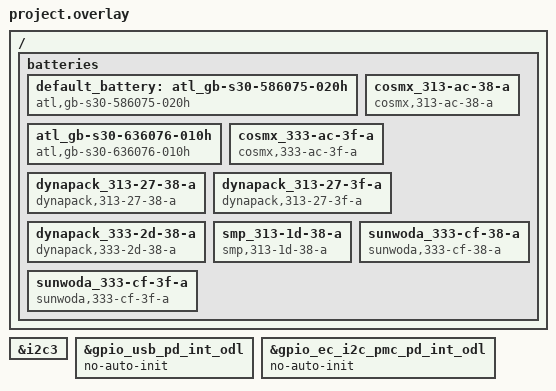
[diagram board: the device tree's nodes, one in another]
/* Copyright 2025 The ChromiumOS Authors
 * Use of this source code is governed by a BSD-style license that can be
 * found in the LICENSE file.
 */

/* Caboc program common DTS includes */

/* Arbitrage generates an incorrect node label when using alternate pins.
 * Create a 2nd node label on I2C3 as a workaround.
 * TODO: b/310227384 - I2C alternate selection not detected automatically.
 */
i2c3ALT: &i2c3 {
};

#include <cros/cbi_flash.dtsi>

#include "../binman.dtsi"
#include "../brox.dtsi"
#include "cbi.dtsi"
#include "fan.dtsi"
#include "gpio.dtsi"
#include "../i2c.dtsi"
#include "../interrupts.dtsi"
#include "../led_pins.dtsi"
#include "../led_policy.dtsi"
#include "keyboard.dtsi"
#include "../power_signals.dtsi"
#include "../power_signals_gpios.dtsi"
#include "../pwm.dtsi"
#include "temp_sensors.dtsi"
#include "../usb_typec.dtsi"
#include "../usba.dtsi"

/* Caboc project DTS includes*/

/* Caboc overrides follow... */

/{
        batteries {
                default_battery: atl_gb-s30-586075-020h {
                        compatible = "atl,gb-s30-586075-020h", "battery-smart";
                };
                atl_gb-s30-636076-010h {
                        compatible = "atl,gb-s30-636076-010h", "battery-smart";
                };
                cosmx_313-ac-38-a {
                        compatible = "cosmx,313-ac-38-a", "battery-smart";
                };
                cosmx_333-ac-3f-a {
                        compatible = "cosmx,333-ac-3f-a", "battery-smart";
                };
                dynapack_313-27-38-a {
                        compatible = "dynapack,313-27-38-a", "battery-smart";
                };
                dynapack_313-27-3f-a {
                        compatible = "dynapack,313-27-3f-a", "battery-smart";
                };
                dynapack_333-2d-38-a {
                        compatible = "dynapack,333-2d-38-a", "battery-smart";
                };
                smp_313-1d-38-a {
                        compatible = "smp,313-1d-38-a", "battery-smart";
                };
                sunwoda_333-cf-38-a {
                        compatible = "sunwoda,333-cf-38-a", "battery-smart";
                };
                sunwoda_333-cf-3f-a {
                        compatible = "sunwoda,333-cf-3f-a", "battery-smart";
                };
        };
};

/* These GPIOS are initialized by the PDC driver */
&gpio_usb_pd_int_odl {
	no-auto-init;
};
&gpio_ec_i2c_pmc_pd_int_odl {
	no-auto-init;
};

/* Caboc does not support motion sense */
/delete-node/ &int_lid_imu;
